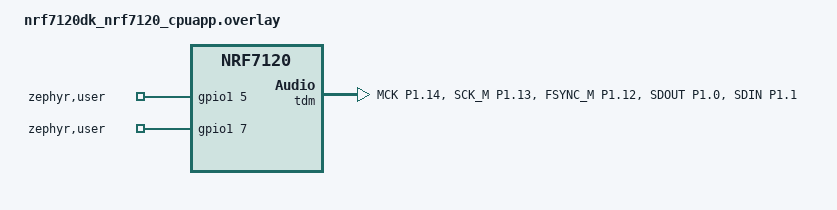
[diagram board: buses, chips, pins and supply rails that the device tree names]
/*
 * Copyright (c) 2025 Nordic Semiconductor ASA
 *
 * SPDX-License-Identifier: LicenseRef-Nordic-5-Clause
 */

/* i2s-node0 is the transmitter/receiver */

/ {
	aliases {
		i2s-node0 = &tdm;
		mck-timer = &timer20;
		lrck-timer = &timer21;
	};

	zephyr,user {
		gpios = <&gpio1 5 GPIO_ACTIVE_HIGH>,  /* Connect with TDM_MCK */
			<&gpio1 7 GPIO_ACTIVE_HIGH>;  /* Connect with TDM_FSYNC_M */
	};
};

&gpio1 {
	status = "okay";
};

&gpiote20 {
	status = "okay";
};

&pinctrl {
	tdm_default_alt: tdm_default_alt {
		group1 {
			psels = <NRF_PSEL(TDM_MCK, 1, 14)>,
				<NRF_PSEL(TDM_SCK_M, 1, 13)>,
				<NRF_PSEL(TDM_FSYNC_M, 1, 12)>,
				<NRF_PSEL(TDM_SDOUT, 1, 0)>,  /* TDM_SDOUT shorted to TDM_SDIN */
				<NRF_PSEL(TDM_SDIN, 1, 1)>;
		};
	};
};

&tdm {
	status = "okay";
	pinctrl-0 = <&tdm_default_alt>;
	pinctrl-names = "default";
	mck-frequency = <64000>;
};
